# A31T51x register map
Vendor: ABOV Semiconductor Co., Ltd.; File version: 1.0
CPU: CM0PLUS r0p1, little endian, no MPU, no FPU, VTOR, 2 interrupt priority bits
Registers are 32-bit, read-write, reset 0x0 unless marked. A register's access mark holds for its fields unless they carry their own. Offsets are from the block's base; [hi:lo] are bit positions; {n}, {i} and the like mark numbered series.

## CFMC — CODE FLASH MEMORY CONTROLLER
Base 0x40080000
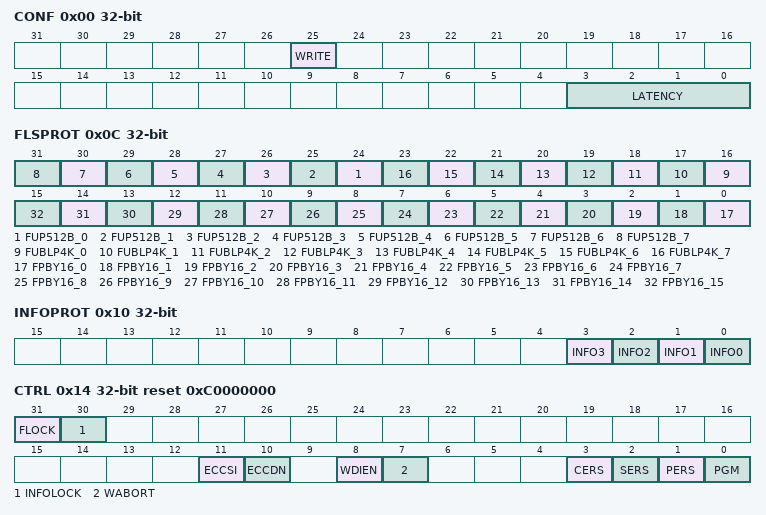
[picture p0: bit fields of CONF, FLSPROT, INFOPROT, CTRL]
0x00 CONF — code flash control register
  [25] WRITE — Code Flash write Enable Bit
    0=Disable write; 1=Enable write
  [3:0] LATENCY — Flash Wait Value Bits
0x04 FLSKEY — code flash access key register
  [31:0] FKEY wo — These bits are the key values used to access the flash memory, KEY1(0x01234567) -> KEY2(0x12345678) -> KEY3(0x23456789)
0x08 INFOKEY — code flash User info access key register
  [31:0] INFOKEY wo — These bits are the key values used to access the flash User info area, KEY1(0x3456789A) -> KEY2(0x456789AB) -> KEY3(0x56789ABC)
0x0C FLSPROT — code flash protection register
  [n+24] FUP512B_{n} (n=0..7) — Unprotection of the 4KB of Flash memory
  [n+16] FUBLP4K_{n} (n=0..7) — Protection for user boot loader area
  [n] FPBY16_{n} (n=0..15) — Flash area protection selection bit
0x10 INFOPROT — code flash info protection register
  [3] INFO3 — INFO3 Area Protection bit, 0x0F00_0600 0x0F00_07FF
  [2] INFO2 — INFO2 Area Protection bit, 0x0F00_0400 0x0F00_05FF
  [1] INFO1 — INFO1 Area Protection bit, 0x0F00_0200 0x0F00_03FF
  [0] INFO0 — INFO0 Area Protection bit, 0x0F00_0000 0x0F00_01FF (Read protection area)
0x14 CTRL reset 0xC0000000 — code flash access control register
  [31] FLOCK — Code flash access control bit
  [30] INFOLOCK — User info access control bit
  [11] ECCSI — ECC single error interrupt enable
    0=Disable interrupt; 1=Enable interrupt
  [10] ECCDN — ECC double error non-maskable interrupt enable
    0=Disable interrupt; 1=Enable interrupt
  [8] WDIEN — Write done interrupt enable
    0=Disable interrupt; 1=Enable interrupt
  [7] WABORT — Write abort settings
    0=Disable (No Effect); 1=Enable (Abort write operation)
  [3] CERS — Whole flash memory erase
    0=Disable bulk erase; 1=Enable bulk erase
  [2] SERS — Flash memory erase in sector units
    0=Disable sector erase; 1=Enable sector erase
  [1] PERS — Flash memory erase in page units
    0=Disable page erase; 1=Enable page erase
  [0] PGM — Program Mode
    0=Disable program; 1=Enable program
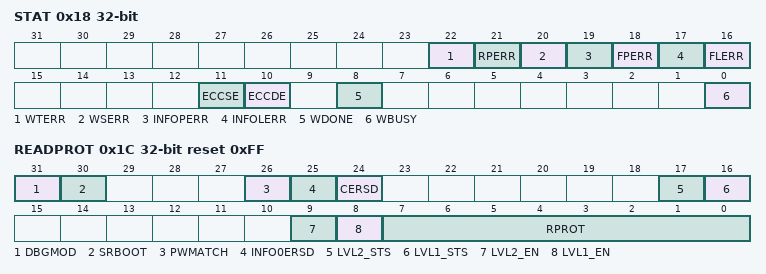
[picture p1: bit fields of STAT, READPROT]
0x18 STAT — code flash access status register
  [22] WTERR — Write timeout error (cleared by writing a '1')
  [21] RPERR — Read-protect error (cleared by writing a '1')
  [20] WSERR — Write sequence error (cleared by writing a '1')
  [19] INFOPERR — INFO protect error (cleared by writing a '1')
  [18] FPERR — Flash protect error (cleared by writing a '1')
  [17] INFOLERR — INFO protect error (cleared by writing a '1')
  [16] FLERR — Flash lock error (cleared by writing a '1')
  [11] ECCSE — Code flash ECC single error (cleared by writing a '1')
  [10] ECCDE — Code flash ECC double error (cleared by writing a '1')
  [8] WDONE — Write done interrupt status (cleared by writing a '1')
  [0] WBUSY ro — Write Busy Check
    0=Not_Busy; 1=Busy
0x1C READPROT reset 0xFF — Flash Read Protection Register
  [31] DBGMOD ro — Debug operating status bit
  [30] SRBOOT ro — SRAM Boot mode status bit
  [26] PWMATCH ro — Password match flag bit
  [25] INFO0ERSD ro — Chip erase and User info 0 erase done flag bit
  [24] CERSD ro — Chip erase done flag bit
  [17] LVL2_STS ro — Protection Level 2 status bit in debug mode This bit can be checked in debug mode only
  [16] LVL1_STS ro — Protection Level 1 status bit in debug mode This bit can be checked in debug mode only
  [9] LVL2_EN ro — Protection Level 2 status bit
  [8] LVL1_EN ro — Protection Level 1 status bit
  [7:0] RPROT — Read protection control bit
    255=Unprotection; 185=PROT_L1_PW (Protection Level 1 Password); 57=PROT_L1 (Protection Level 1); 128=PROT_L2_PW (Protection Level 2 Password); 0=PROT_L2 (Protection Level 2)
0x20 PWIN wo — code flash password input register
  [31:0] PWIN — Password input data bit
0x40 WTIMEOUT — code flash write time-out register
  [31:0] WTIMEOUT — Flash write time-out setting bit
0x60 ECCEADDR — Code Flash ECC Error Address Register
  [31:0] ECCEA — ECC error address
0x64 ECCEDATA — Code Flash ECC Error Data Address Register
  [31:0] ECCED — ECC error data
0x74 ECCPARITY — Code Flash ECC Error Parity Register
  [31:0] ECCEP — ECC error parity
0xF18 PWPRST wo — code flash password preset register
  [31:0] PWPRST — Password preset data bit
